# APM32F103xC register map
File version: 1.0
CPU: CM3 r2p1, little endian, no MPU, no FPU, 4 interrupt priority bits
Registers are 32-bit, read-write, reset 0x0 unless marked. A register's access mark holds for its fields unless they carry their own. Offsets are from the block's base; [hi:lo] are bit positions; {n}, {i} and the like mark numbered series; 'fields as' and 'values as' point back to an identical list.

## DBGMCU — Debug support
Base 0xE0042000
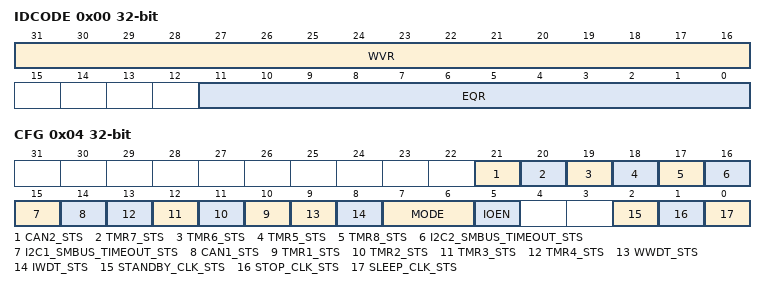
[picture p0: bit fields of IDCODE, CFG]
0x00 IDCODE ro — DBGMCU_IDCODE
  [31:16] WVR — Wafer Version Recognition
  [11:0] EQR — Equipment Recognition
0x04 CFG — DBGMCU_CFG
  [21] CAN2_STS, [20] TMR7_STS, [19] TMR6_STS, [18] TMR5_STS, [17] TMR8_STS, [16] I2C2_SMBUS_TIMEOUT_STS, [15] I2C1_SMBUS_TIMEOUT_STS, [14] CAN1_STS, [n+9] TMR{n}_STS (n=1..4), [9] WWDT_STS, [8] IWDT_STS, [7:6] MODE, [5] IOEN, [2] STANDBY_CLK_STS, [1] STOP_CLK_STS, [0] SLEEP_CLK_STS

## SDIO — Secure digital input/output interface
Base 0x40018000
0x00 PWRCTRL — Bits 1:0 = PWRCTRL: Power supply control bits
  [1:0] PWRCTRL
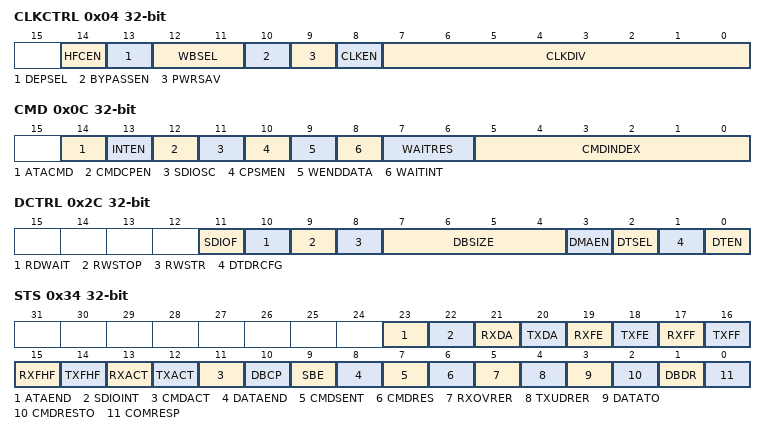
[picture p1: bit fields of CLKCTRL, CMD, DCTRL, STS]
0x04 CLKCTRL — SDI clock control register (SDIO_CLKCR)
  [14] HFCEN — HW Flow Control enable
  [13] DEPSEL — SDIO_CK dephasing selection bit
  [12:11] WBSEL — Wide bus mode enable bit
  [10] BYPASSEN — Clock divider bypass enable bit
  [9] PWRSAV — Power saving configuration bit
  [8] CLKEN — Clock enable bit
  [7:0] CLKDIV — Clock divide factor
0x08 ARG — Bits 31:0 = : Command argument
  [31:0] CMDARG — Command argument
0x0C CMD — SDIO command register (SDIO_CMD)
  [14] ATACMD, [13] INTEN, [12] CMDCPEN, [11] SDIOSC, [10] CPSMEN, [9] WENDDATA, [8] WAITINT, [7:6] WAITRES, [5:0] CMDINDEX
0x10 CMDRES ro — SDIO command register
  [5:0] CMDRES
{0x10+4i} RES{i} ro (i=1..4) — Bits 31:0 = CARDSTATUS{i}
  [31:0] CARDSTS{i}
0x24 DATATIME — Bits 31:0 = DATATIME: Data timeout period
  [31:0] DATATIME — Data timeout period
0x28 DATALEN — Bits 24:0 = DATALENGTH: Data length value
  [24:0] DATALEN — Data length value
0x2C DCTRL — SDIO data control register (SDIO_DCTRL)
  [11] SDIOF, [10] RDWAIT, [9] RWSTOP, [8] RWSTR, [7:4] DBSIZE, [3] DMAEN, [2] DTSEL, [1] DTDRCFG, [0] DTEN
0x30 DCNT ro — Bits 24:0 = DATACOUNT: Data count value
  [24:0] DATACNT — Data count value
0x34 STS ro — SDIO status register (SDIO_STS)
  [23] ATAEND, [22] SDIOINT, [21] RXDA, [20] TXDA, [19] RXFE, [18] TXFE, [17] RXFF, [16] TXFF, [15] RXFHF, [14] TXFHF, [13] RXACT, [12] TXACT, [11] CMDACT, [10] DBCP, [9] SBE, [8] DATAEND, [7] CMDSENT, [6] CMDRES, [5] RXOVRER, [4] TXUDRER, [3] DATATO, [2] CMDRESTO, [1] DBDR, [0] COMRESP
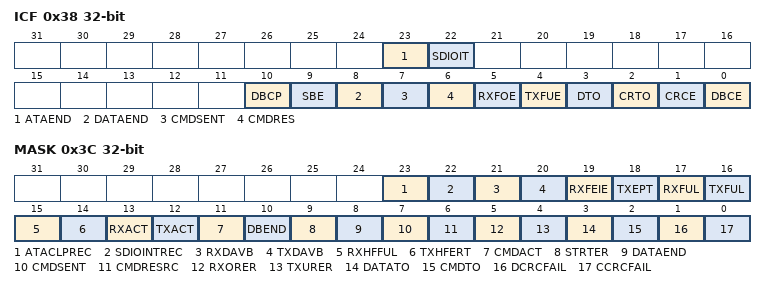
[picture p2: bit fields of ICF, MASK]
0x38 ICF — SDIO interrupt clear register (SDIO_ICF)
  [23] ATAEND, [22] SDIOIT, [10] DBCP, [9] SBE, [8] DATAEND, [7] CMDSENT, [6] CMDRES, [5] RXFOE, [4] TXFUE, [3] DTO, [2] CRTO, [1] CRCE, [0] DBCE
0x3C MASK — SDIO mask register (SDIO_MASK)
  [23] ATACLPREC
  [22] SDIOINTREC
  [21] RXDAVB
  [20] TXDAVB
  [19] RXFEIE
  [18] TXEPT
  [17] RXFUL
  [16] TXFUL
  [15] RXHFFUL
  [14] TXHFERT — TXFERT
  [13] RXACT
  [12] TXACT
  [11] CMDACT
  [10] DBEND
  [9] STRTER
  [8] DATAEND
  [7] CMDSENT
  [6] CMDRESRC
  [5] RXORER
  [4] TXURER
  [3] DATATO
  [2] CMDTO
  [1] DCRCFAIL
  [0] CCRCFAIL
0x48 FIFOCNT ro — Bits 23:0 = FIFOCOUNT: Remaining number of words to be written to or read from the FIFO
  [23:0] FIFOCNT
0x80 FIFODATA — bits 31:0 = FIFOData: Receive and transmit FIFO data

## EMMC
Base 0xA0000000
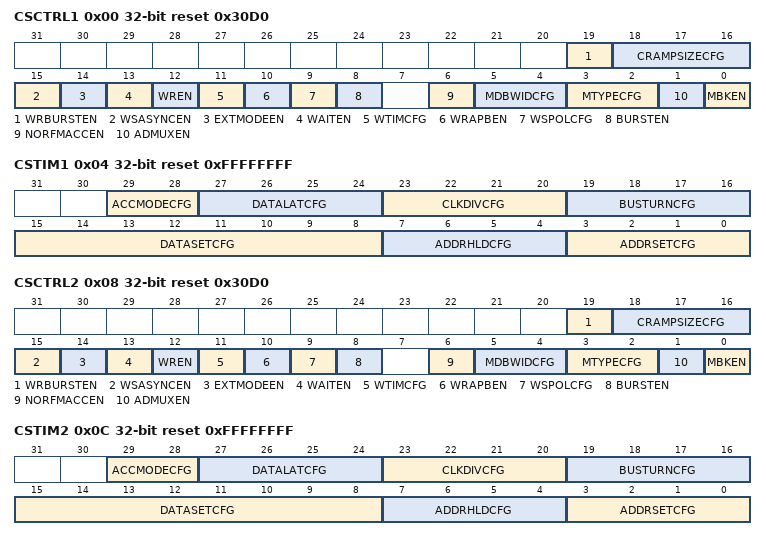
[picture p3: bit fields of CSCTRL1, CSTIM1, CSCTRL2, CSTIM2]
0x00 CSCTRL1 reset 0x30D0 — SRAM/NOR-Flash chip-select control register 1
  [19] WRBURSTEN, [18:16] CRAMPSIZECFG, [15] WSASYNCEN, [14] EXTMODEEN, [13] WAITEN, [12] WREN, [11] WTIMCFG, [10] WRAPBEN, [9] WSPOLCFG, [8] BURSTEN, [6] NORFMACCEN, [5:4] MDBWIDCFG, [3:2] MTYPECFG, [1] ADMUXEN, [0] MBKEN
0x04 CSTIM1 reset 0xFFFFFFFF — SRAM/NOR-Flash chip-select timing register 1
  [29:28] ACCMODECFG, [27:24] DATALATCFG, [23:20] CLKDIVCFG, [19:16] BUSTURNCFG, [15:8] DATASETCFG, [7:4] ADDRHLDCFG, [3:0] ADDRSETCFG
0x08 CSCTRL2 reset 0x30D0 — SRAM/NOR-Flash chip-select control register 2
  fields as CSCTRL1
0x0C CSTIM2 reset 0xFFFFFFFF — SRAM/NOR-Flash chip-select timing register 2
  fields as CSTIM1
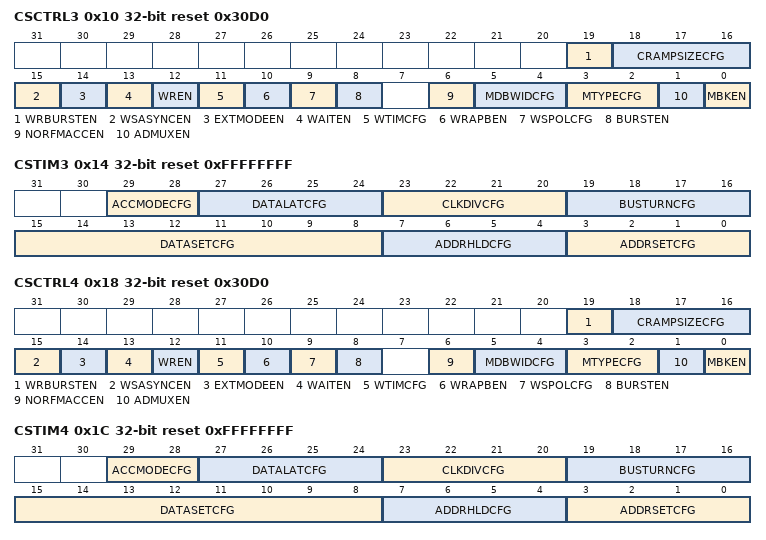
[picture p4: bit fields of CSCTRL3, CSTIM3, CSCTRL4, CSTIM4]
0x10 CSCTRL3 reset 0x30D0 — SRAM/NOR-Flash chip-select control register 3
  fields as CSCTRL1
0x14 CSTIM3 reset 0xFFFFFFFF — SRAM/NOR-Flash chip-select timing register 3
  fields as CSTIM1
0x18 CSCTRL4 reset 0x30D0 — SRAM/NOR-Flash chip-select control register 4
  fields as CSCTRL1
0x1C CSTIM4 reset 0xFFFFFFFF — SRAM/NOR-Flash chip-select timing register 4
  fields as CSTIM1
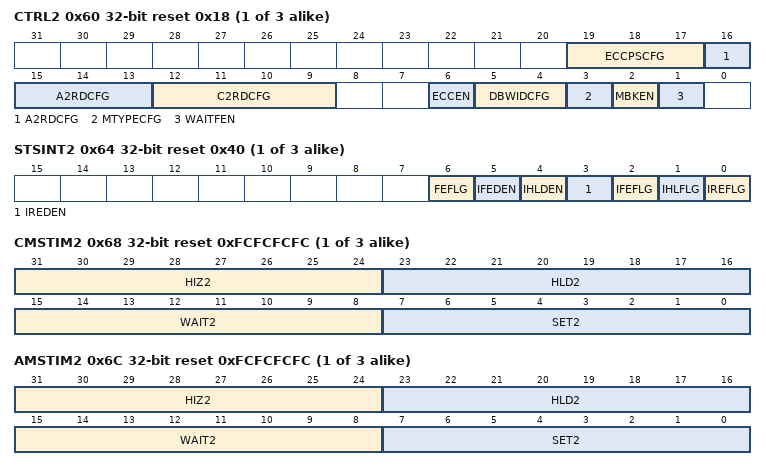
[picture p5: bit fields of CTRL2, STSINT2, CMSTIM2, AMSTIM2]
{0x20+0x20*i} CTRL{i} reset 0x18 (i=2..4) — PC Card/NAND Flash control register {i}
  [19:17] ECCPSCFG
  [16:13] A2RDCFG
  [12:9] C2RDCFG — C2RDCF
  [6] ECCEN
  [5:4] DBWIDCFG
  [3] MTYPECFG
  [2] MBKEN
  [1] WAITFEN
{0x24+0x20*i} STSINT{i} access per field reset 0x40 (i=2..4) — FIFO status and interrupt register {i}
  [6] FEFLG ro, [5] IFEDEN rw, [4] IHLDEN rw, [3] IREDEN rw, [2] IFEFLG rw, [1] IHLFLG rw, [0] IREFLG rw
{0x28+0x20*i} CMSTIM{i} reset 0xFCFCFCFC (i=2..4) — Common memory space timing register {i}
  [31:24] HIZ{i} — Common memory {i} databus HiZ time
  [23:16] HLD{i} — Common memory {i} hold time
  [15:8] WAIT{i} — Common memory {i} wait time
  [7:0] SET{i} — Common memory {i} setup time
{0x2C+0x20*i} AMSTIM{i} reset 0xFCFCFCFC (i=2..4) — Attribute memory space timing register {i}
  [31:24] HIZ{i} — Attribute memory {i} databus HiZ time
  [23:16] HLD{i} — Attribute memory {i} hold time
  [15:8] WAIT{i} — Attribute memory {i} wait time
  [7:0] SET{i} — Attribute memory {i} setup time
0x74 ECCRS2 ro — ECC result register 2
  [31:0] ECCRS2 — ECC result 2
0x94 ECCRS3 ro — ECC result register 3
  [31:0] ECCRS3 — ECC result 3
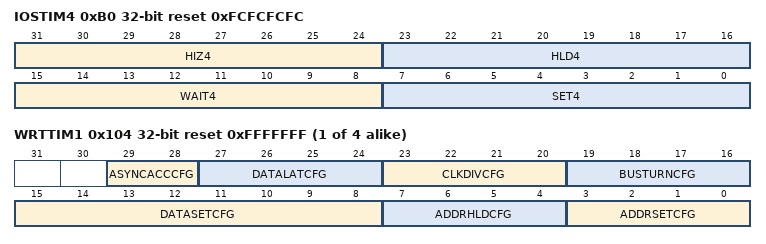
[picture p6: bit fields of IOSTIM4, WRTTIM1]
0xB0 IOSTIM4 reset 0xFCFCFCFC — I/O space timing register 4
  [31:24] HIZ4, [23:16] HLD4, [15:8] WAIT4, [7:0] SET4
{0xFC+8i} WRTTIM{i} reset 0xFFFFFFF (i=1..4) — SRAM/NOR-Flash write timing registers {i}
  [29:28] ASYNCACCCFG, [27:24] DATALATCFG, [23:20] CLKDIVCFG, [19:16] BUSTURNCFG, [15:8] DATASETCFG, [7:4] ADDRHLDCFG, [3:0] ADDRSETCFG

## DMC — Dynamic memory controler
Base 0xA0000000
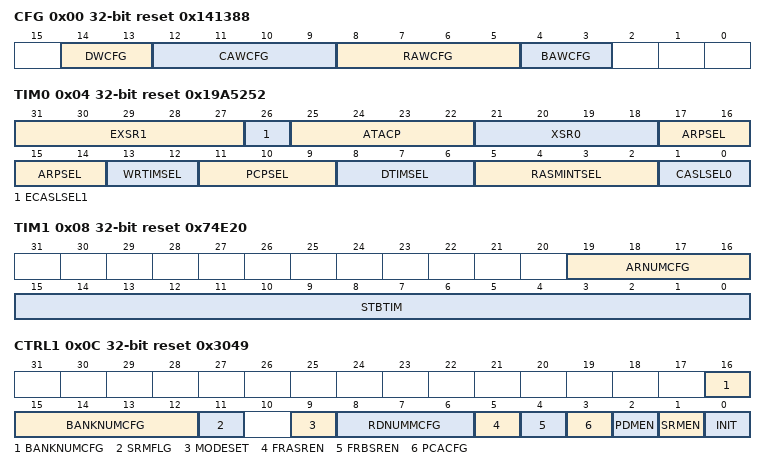
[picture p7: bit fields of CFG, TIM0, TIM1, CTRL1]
0x00 CFG reset 0x141388 — Configuraion register
  [14:13] DWCFG, [12:9] CAWCFG, [8:5] RAWCFG, [4:3] BAWCFG
0x04 TIM0 reset 0x19A5252 — Timing register 0
  [31:27] EXSR1, [26] ECASLSEL1, [25:22] ATACP, [21:18] XSR0, [17:14] ARPSEL, [13:12] WRTIMSEL, [11:9] PCPSEL, [8:6] DTIMSEL, [5:2] RASMINTSEL, [1:0] CASLSEL0
0x08 TIM1 reset 0x74E20 — Timing register 1
  [19:16] ARNUMCFG, [15:0] STBTIM
0x0C CTRL1 access per field reset 0x3049 — Control register 1
  [16:12] BANKNUMCFG rw
  [11] SRMFLG ro
  [9] MODESET rw
  [8:6] RDNUMMCFG rw — RDNUMCFG
  [5] FRASREN rw
  [4] FRBSREN rw
  [3] PCACFG rw
  [2] PDMEN rw
  [1] SRMEN rw
  [0] INIT rw
0x10 REF reset 0xC3 — refresh register
  [15:0] RCYCCFG
0x14 CHIPSEL — Chip select register
  [31:16] BACHIPSEL
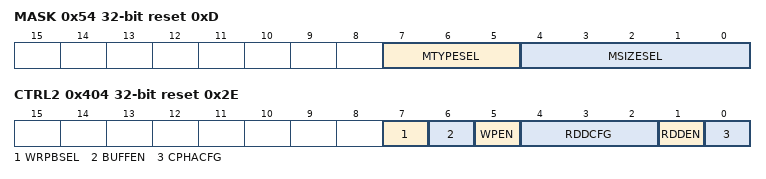
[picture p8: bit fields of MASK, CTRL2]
0x54 MASK reset 0xD
  [7:5] MTYPESEL, [4:0] MSIZESEL
0x400 SW — switch register
  [0] MCSW — Memory Controller Function Switch
0x404 CTRL2 reset 0x2E — Control register 2
  [7] WRPBSEL, [6] BUFFEN, [5] WPEN, [4:2] RDDCFG, [1] RDDEN, [0] CPHACFG

## USBD — Universal serial bus full-speed device interface
Base 0x40005C00
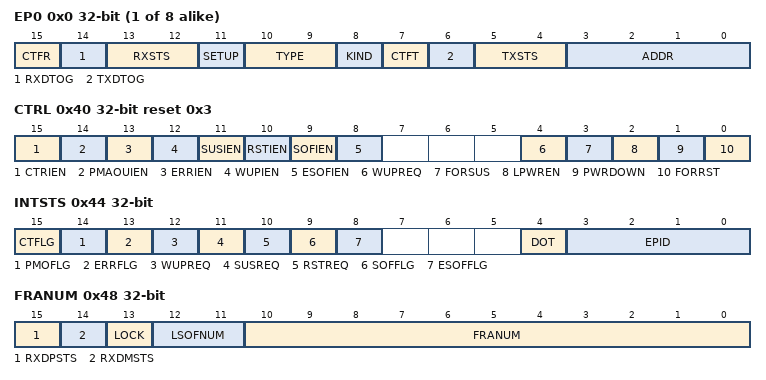
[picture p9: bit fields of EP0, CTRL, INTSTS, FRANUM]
{0x0+4i} EP{i} (i=0..7) — endpoint {i} register
  [15] CTFR — Correct transfer for reception
  [14] RXDTOG — Data Toggle, for reception transfers
  [13:12] RXSTS — Status bits, for reception transfers
  [11] SETUP — Setup transaction completed
  [10:9] TYPE — Endpoint type
  [8] KIND — Endpoint kind
  [7] CTFT — Correct Transfer for transmission
  [6] TXDTOG — Data Toggle, for transmission transfers
  [5:4] TXSTS — Status bits, for transmission transfers
  [3:0] ADDR — Endpoint address
0x40 CTRL reset 0x3 — control register
  [15] CTRIEN — Correct transfer interrupt mask
  [14] PMAOUIEN — Packet memory area over / underrun interrupt mask
  [13] ERRIEN — Error interrupt mask
  [12] WUPIEN — Wakeup interrupt mask
  [11] SUSIEN — Suspend mode interrupt mask
  [10] RSTIEN — USB reset interrupt mask
  [9] SOFIEN — Start of frame interrupt mask
  [8] ESOFIEN — Expected start of frame interrupt mask
  [4] WUPREQ — Wakeup request
  [3] FORSUS — Force suspend
  [2] LPWREN — Low-power mode
  [1] PWRDOWN — Power down
  [0] FORRST — Force USB Reset
0x44 INTSTS — interrupt status register
  [15] CTFLG — Correct transfer
  [14] PMOFLG — Packet memory area over / underrun
  [13] ERRFLG — Error
  [12] WUPREQ — Wakeup
  [11] SUSREQ — Suspend mode request
  [10] RSTREQ — reset request
  [9] SOFFLG — start of frame
  [8] ESOFFLG — Expected start frame
  [4] DOT — Direction of transaction
  [3:0] EPID — Endpoint Identifier
0x48 FRANUM ro — frame number register
  [15] RXDPSTS — Receive data + line status
  [14] RXDMSTS — Receive data - line status
  [13] LOCK — Locked
  [12:11] LSOFNUM — Lost SOF
  [10:0] FRANUM — Frame number
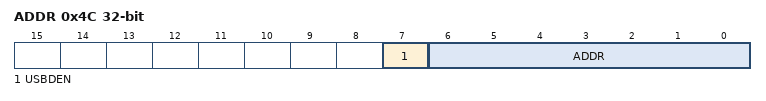
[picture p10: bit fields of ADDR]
0x4C ADDR — device address
  [7] USBDEN — Enable function
  [6:0] ADDR — Device address
0x50 BUFFTB — Buffer table address
  [15:3] BUFFTB — Buffer table
0x100 SWITCH
  [0] SWITCH
